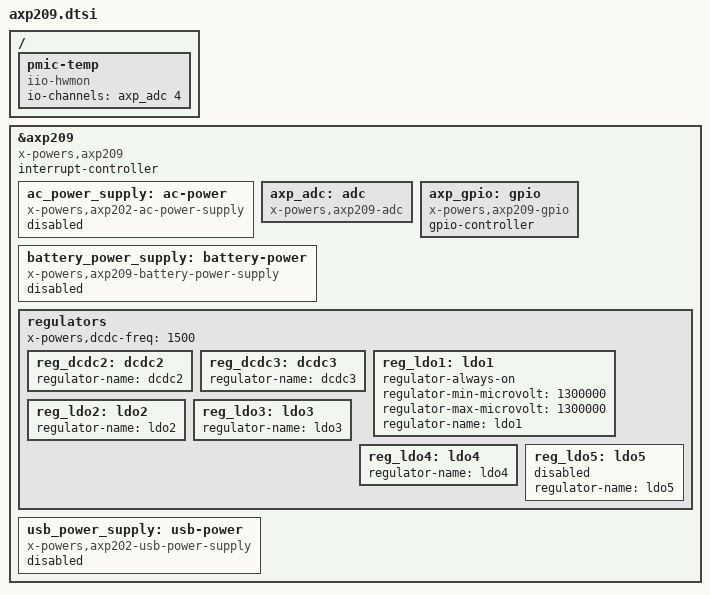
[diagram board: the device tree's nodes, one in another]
/ {
	pmic-temp {
		compatible = "iio-hwmon";
		io-channels = <&axp_adc 4>;  
	};
};
&axp209 {
	compatible = "x-powers,axp209";
	interrupt-controller;
	#interrupt-cells = <1>;
	ac_power_supply: ac-power {
		compatible = "x-powers,axp202-ac-power-supply";
		status = "disabled";
	};
	axp_adc: adc {
		compatible = "x-powers,axp209-adc";
		#io-channel-cells = <1>;
	};
	axp_gpio: gpio {
		compatible = "x-powers,axp209-gpio";
		gpio-controller;
		#gpio-cells = <2>;
	};
	battery_power_supply: battery-power {
		compatible = "x-powers,axp209-battery-power-supply";
		status = "disabled";
	};
	regulators {
		x-powers,dcdc-freq = <1500>;
		reg_dcdc2: dcdc2 {
			regulator-name = "dcdc2";
		};
		reg_dcdc3: dcdc3 {
			regulator-name = "dcdc3";
		};
		reg_ldo1: ldo1 {
			regulator-always-on;
			regulator-min-microvolt = <1300000>;
			regulator-max-microvolt = <1300000>;
			regulator-name = "ldo1";
		};
		reg_ldo2: ldo2 {
			regulator-name = "ldo2";
		};
		reg_ldo3: ldo3 {
			regulator-name = "ldo3";
		};
		reg_ldo4: ldo4 {
			regulator-name = "ldo4";
		};
		reg_ldo5: ldo5 {
			regulator-name = "ldo5";
			status = "disabled";
		};
	};
	usb_power_supply: usb-power {
		compatible = "x-powers,axp202-usb-power-supply";
		status = "disabled";
	};
};
